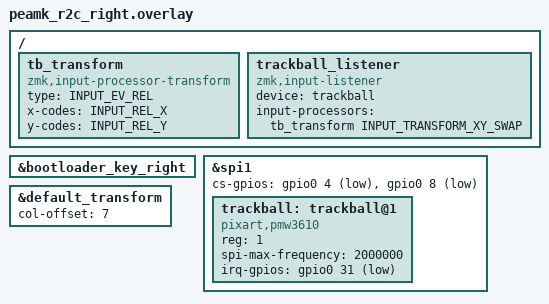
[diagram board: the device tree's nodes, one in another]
/*
 * Copyright (c) 2022 The ZMK Contributors
 *
 * SPDX-License-Identifier: MIT
 */

#include "peamk_r2c.dtsi"
#include <zephyr/dt-bindings/input/input-event-codes.h>
#include <dt-bindings/zmk/input_transform.h>

&bootloader_key_right {
    status = "okay";
};

/ {

};

/*
 * PMW3610 Trackball via VIK
 * Append VIK CS to existing shift register CS
 * Trackball at reg 1 (shift register is reg 0)
 */
&spi1 {
    cs-gpios = <&gpio0 4 GPIO_ACTIVE_LOW>, <&gpio0 8 GPIO_ACTIVE_LOW>;

    trackball: trackball@1 {
        compatible = "pixart,pmw3610";
        status = "okay";
        reg = <1>;
        spi-max-frequency = <2000000>;
        irq-gpios = <&gpio0 31 (GPIO_ACTIVE_LOW | GPIO_PULL_UP)>;
    };
};

/ {
    tb_transform: tb_transform {
        compatible = "zmk,input-processor-transform";
        #input-processor-cells = <1>;
        type = <INPUT_EV_REL>;
        x-codes = <INPUT_REL_X>;
        y-codes = <INPUT_REL_Y>;
    };

    trackball_listener {
        compatible = "zmk,input-listener";
        device = <&trackball>;
        input-processors = <&tb_transform INPUT_TRANSFORM_XY_SWAP>;
    };
};

&default_transform {
    col-offset = <7>;
};
